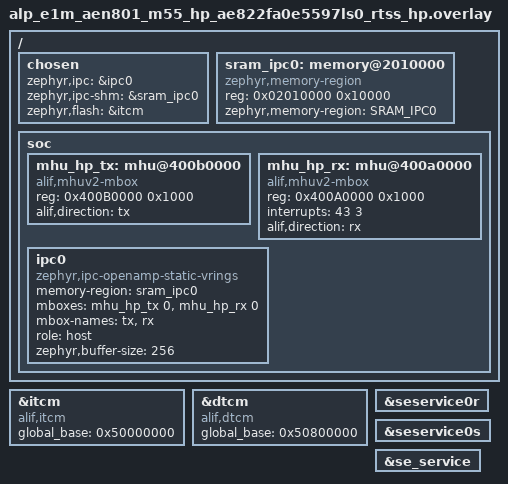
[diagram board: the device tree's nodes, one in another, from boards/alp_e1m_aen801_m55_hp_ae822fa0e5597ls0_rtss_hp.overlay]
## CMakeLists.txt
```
# SPDX-License-Identifier: Apache-2.0
#
# aen-alp-rpc -- the proven aen-rpc-pingpong transport driven through the
# portable <alp/rpc.h> surface.  Build for BOTH boards; each board's
# fully-qualified boards/<board>.overlay auto-applies (the MHU frames + shared
# SRAM0 carve-out + ipc0 host/remote + SE-service nodes).  The HP build is the
# host (boots HE, sends "ping"); the HE build is the remote (echoes "pong").
#
# NOTE: open-amp + libmetal are alp-sdk west projects (the manifest allowlists
# the Zephyr-pinned modules), so a `west update` fetches them and they are
# auto-discovered -- no manual -DEXTRA_ZEPHYR_MODULES for them:
#   west build -p always -b alp_e1m_aen801_m55_hp/ae822fa0e5597ls0/rtss_hp \
#       examples/aen/aen-alp-rpc -d build-hp -- \
#       "-DEXTRA_ZEPHYR_MODULES=/path/alp-sdk;/path/hal/alif"
cmake_minimum_required(VERSION 3.20)
find_package(Zephyr REQUIRED HINTS $ENV{ZEPHYR_BASE})
project(aen_alp_rpc LANGUAGES C)
target_sources(app PRIVATE src/main.c)
```

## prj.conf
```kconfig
# SPDX-License-Identifier: Apache-2.0
#
# aen-alp-rpc -- the bench-proven aen-rpc-pingpong transport (PR#205, 16/16
# PASS) driven through the portable <alp/rpc.h> surface instead of the raw
# ipc_service calls.  The Kconfig is identical to pingpong's: the alp_rpc
# Zephyr backend binds the very same ipc0 instance the pingpong example does
# (it resolves DT_CHOSEN(zephyr_ipc) and runs ipc_service_open_instance +
# ipc_service_register_endpoint behind alp_rpc_open()).
#
# Bench RAM-run: console is the Alp UART console on the E1M edge UART0 (see the
# console block below).

# CONFIG_ALP_SDK turns on the alp-sdk module sources (the dispatcher in
# src/rpc_dispatch.c + the Zephyr backend in src/backends/rpc/zephyr_drv.c) and
# the Tier-2 driver Kconfigs (CONFIG_MBOX_ALIF_MHUV2 / CONFIG_ARM_MHUV2 /
# CONFIG_HAS_ALIF_SE_SERVICES).
CONFIG_ALP_SDK=y

# --- IPC / OpenAMP stack ---------------------------------------------------
# MBOX is the doorbell class; CONFIG_MBOX_ALIF_MHUV2 builds the Alif MHUv2 MBOX
# driver (zephyr/drivers/mbox/mbox_alif_mhuv2.c) for the ipc0 'mboxes'.
CONFIG_MBOX=y
CONFIG_MBOX_ALIF_MHUV2=y

# ipc_service + the OpenAMP RPMsg static-vrings backend.  alp_rpc's backend
# requires all three (zephyr_drv.c #errors otherwise) and the Kconfig
# (ALP_SDK_RPC: depends on IPC_SERVICE_BACKEND_RPMSG && OPENAMP) gates on them.
CONFIG_IPC_SERVICE=y
CONFIG_IPC_SERVICE_BACKEND_RPMSG=y
CONFIG_OPENAMP=y

# The framed-RPC body in src/backends/rpc/zephyr_drv.c.  default-y once
# IPC_SERVICE_BACKEND_RPMSG is set, but pin it so the build is self-describing.
CONFIG_ALP_SDK_RPC=y

# OpenAMP/libmetal need a heap for the rpmsg virtio allocations + the RX work
# queue.  Size generously for the RAM-run.
CONFIG_HEAP_MEM_POOL_SIZE=16384
CONFIG_MAIN_STACK_SIZE=4096
CONFIG_SYSTEM_WORKQUEUE_STACK_SIZE=2048

# --- SE service (HP boots HE via the portable alp_mproc_boot_core) ---------
# CONFIG_ARM_MHUV2 builds the in-tree "arm,mhuv2" IPM driver
# (zephyr/drivers/ipm/ipm_arm_mhuv2.c) for the seservice0 transport;
# CONFIG_HAS_ALIF_SE_SERVICES compiles the hal_alif SE client the SDK's boot
# backend (CONFIG_ALP_SDK_MPROC_BOOT_ALIF_SE, default y) consumes.
CONFIG_ARM_MHUV2=y
CONFIG_HAS_ALIF_SE_SERVICES=y

# --- Console: Alp UART console -- E1M edge UART0 (Alif UART5, P3_4/P3_5, 115200
# 8N1, NS16550), the E1M-AEN801 carrier console. The board _defconfig already
# selects it; we set it explicitly here so the example is self-describing.
CONFIG_SERIAL=y
CONFIG_CONSOLE=y
CONFIG_UART_CONSOLE=y
CONFIG_UART_INTERRUPT_DRIVEN=y
# Serial-less bench? Comment the four lines above and uncomment these to read
# 'ram_console_buf' over SWD instead:
# CONFIG_RAM_CONSOLE=y
# CONFIG_RAM_CONSOLE_BUFFER_SIZE=2048
# CONFIG_UART_CONSOLE=n
CONFIG_PRINTK=y

# Keep LOG off to keep the image small + deterministic for this bench run.
# alp_rpc's zephyr_drv.c uses LOG_* but those are compiled out cleanly at
# LOG=n.
CONFIG_LOG=n

# DCACHE off: the SRAM0 shared region is addressed identically by both cores and
# carries the vrings; running it cached would need explicit flush/invalidate the
# static-vrings backend doesn't do for this carve-out.  Matches the bench's
# eth/NPU SRAM0 precedent and the proven pingpong config.
CONFIG_DCACHE=n
CONFIG_IPC_SERVICE_BACKEND_RPMSG_SHMEM_RESET=y
```

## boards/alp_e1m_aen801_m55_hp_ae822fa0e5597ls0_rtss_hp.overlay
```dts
/*
 * Copyright (c) 2026 Alp Lab AB
 * SPDX-License-Identifier: Apache-2.0
 *
 * aen-alp-rpc -- M55-HP (ipc0 HOST / vring master) overlay.
 *
 * Byte-for-byte the SAME transport the bench-proven aen-rpc-pingpong overlay
 * wires (PR#205, 16/16 PASS); the only thing that differs between the two
 * examples is the application code -- this one drives the round-trips through
 * the portable <alp/rpc.h> surface instead of the raw ipc_service calls.  The
 * alp_rpc Zephyr backend (src/backends/rpc/zephyr_drv.c) resolves
 * DT_CHOSEN(zephyr_ipc), so the chosen { zephyr,ipc = &ipc0 } node below is the
 * single hook that lets alp_rpc_open() find this exact ipc0 instance.
 *
 * Three pieces (all transcribed verbatim from the proven pingpong overlay):
 *
 *   1. SE-service nodes + per-core itcm/dtcm global_base -- the HP app releases
 *      HE via se_service_boot_cpu() (hal_alif se_service.c puts its outbound
 *      buffer through local_to_global(), which reads
 *      DT_PROP(itcm/dtcm, global_base)).  HP global TCM aliases ITCM 0x50000000
 *      / DTCM 0x50800000, from the zephyr_alif fork ensemble_rtss_hp.dtsi.
 *
 *   2. The two MHUv2 frames this core drives, via the alif,mhuv2-mbox MBOX
 *      driver (zephyr/drivers/mbox/mbox_alif_mhuv2.c).  HP is the host:
 *        - tx (HP -> HE) : non-secure MHU-1 per-core alias @0x400B0000
 *        - rx (HE -> HP) : MHU1 HP-RX window @0x400A0000, HP IRQ 43
 *      Addresses + IRQ are clean-room-transcribed from the Alif DFP E8 part
 *      (AE822FA0E5597, rtss_hp/soc.h):
 *        MHU_M55HE_M55HP_1_RX_BASE = 0x400A0000, MHU_M55HE_M55HP_1_RX_IRQn = 43
 *      The HE -> HP direction is bench-proven by aen-dualcore-doorbell
 *      (commit b81a3738) and by aen-rpc-pingpong (PR#205, 16/16).
 *
 *   3. A shared-memory carve-out in global SRAM0 + the ipc0 node.  SRAM0 global
 *      base 0x02000000 / size 4MB (DFP soc_features.h: SOC_FEAT_BULK_SRAM0_BASE
 *      / _SIZE) is identically addressable from both M55 cores, so the RPMsg
 *      static vrings live here.  Both overlays MUST agree on this region's base
 *      + size + buffer-size.
 *
 * vendor-ext, BENCH-UNVERIFIED for this example's app code; the transport
 * (MHU + vrings + ipc_service handshake) is the bench-proven pingpong config.
 */

#include <zephyr/dt-bindings/ipc_service/static_vrings.h>

/ {
	chosen {
		/* alp_rpc's zephyr_drv.c resolves DT_CHOSEN(zephyr_ipc). */
		zephyr,ipc     = &ipc0;
		zephyr,ipc-shm = &sram_ipc0;
	};

	/*
	 * Shared RPMsg region: SRAM0 @0x02010000, 64 KiB.  Placed 64 KiB above
	 * the SRAM0 base so it never overlaps the 0x0200_00xx bench beacons the
	 * app stamps.  zephyr,memory-region makes it a real linker region; both
	 * cores map the SAME global address.
	 */
	sram_ipc0: memory@2010000 {
		compatible = "zephyr,memory-region", "mmio-sram";
		reg = <0x02010000 0x10000>;
		zephyr,memory-region = "SRAM_IPC0";
	};

	soc {
		/*
		 * HP -> HE sender frame. The non-secure MHU-1 base is a CPU-RELATIVE
		 * ALIAS (proven in aen-dualcore-ipc): from HP, 0x400B0000 = "my TX to
		 * HE" and the fabric routes it into HE's RX @0x400A0000 -- the SAME
		 * pair the HE->HP doorbell uses, no separate MHU0 needed.
		 */
		mhu_hp_tx: mhu@400b0000 {
			compatible = "alif,mhuv2-mbox";
			reg = <0x400B0000 0x1000>;
			alif,direction = "tx";
			#mbox-cells = <1>;
			status = "okay";
		};

		/* HE -> HP receiver frame (MHU1 RX window). */
		mhu_hp_rx: mhu@400a0000 {
			compatible = "alif,mhuv2-mbox";
			reg = <0x400A0000 0x1000>;
			interrupts = <43 3>;
			alif,direction = "rx";
			#mbox-cells = <1>;
			status = "okay";
		};

		ipc0: ipc0 {
			compatible = "zephyr,ipc-openamp-static-vrings";
			memory-region = <&sram_ipc0>;
			mboxes = <&mhu_hp_tx 0>, <&mhu_hp_rx 0>;
			mbox-names = "tx", "rx";
			role = "host";
			zephyr,buffer-size = <256>;
			status = "okay";
		};
	};
};

/*
 * RAM-run: retarget ROM to ITCM (path-reference form &itcm; the phandle-array
 * form makes FLASH_SIZE=0 and overflows the link).
 */
/ {
	chosen {
		zephyr,flash = &itcm;
		/delete-property/ zephyr,code-partition;
	};
};

&itcm {
	compatible = "alif,itcm";
	global_base = <0x50000000>;
};

&dtcm {
	compatible = "alif,dtcm";
	global_base = <0x50800000>;
};

&seservice0r {
	status = "okay";
};

&seservice0s {
	status = "okay";
};

&se_service {
	status = "okay";
};
```

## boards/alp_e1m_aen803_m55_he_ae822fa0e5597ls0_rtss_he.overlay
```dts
/*
 * Copyright (c) 2026 Alp Lab AB
 * SPDX-License-Identifier: Apache-2.0
 *
 * aen-alp-rpc -- M55-HE (ipc0 REMOTE / vring slave) overlay.
 *
 * The mirror of the HP host overlay, and byte-for-byte the SAME transport the
 * bench-proven aen-rpc-pingpong HE overlay wires (PR#205, 16/16 PASS).  HE is
 * the remote, so its tx/rx frames are the OPPOSITE windows of the same two MHU
 * instances:
 *   - tx (HE -> HP) : MHU1 HE-TX window @0x400B0000, HE IRQ 44
 *   - rx (HP -> HE) : MHU1 HE-RX window @0x400A0000, HE IRQ 43 (per-core alias)
 *
 * Addresses + IRQ are clean-room-transcribed from the Alif DFP E8 part
 * (AE822FA0E5597, rtss_he/soc.h):
 *   MHU_M55HE_M55HP_1_TX_BASE = 0x400B0000, MHU_M55HE_M55HP_1_TX_IRQn = 44
 * The HE -> HP TX window (0x400B0000) is bench-proven by aen-dualcore-doorbell
 * (commit b81a3738) and aen-rpc-pingpong (PR#205).
 *
 * The shared SRAM0 carve-out (sram_ipc0 @0x02010000, 64 KiB) and the ipc0
 * buffer-size MUST match the HP overlay byte-for-byte -- the static vrings are
 * laid out by address, so host and remote have to agree.
 *
 * SE-service nodes + itcm/dtcm global_base are enabled here too: the HE app
 * does not itself call boot_cpu in this example, but keeping the SE transport
 * + the HE global TCM aliases (ITCM 0x58000000 / DTCM 0x58800000, from the fork
 * ensemble_rtss_he.dtsi) bound matches the proven pingpong HE overlay and keeps
 * the two builds symmetric.
 *
 * vendor-ext, BENCH-UNVERIFIED for this example's app code; the transport is
 * the bench-proven pingpong config.
 */

#include <zephyr/dt-bindings/ipc_service/static_vrings.h>

/ {
	chosen {
		zephyr,ipc     = &ipc0;
		zephyr,ipc-shm = &sram_ipc0;
	};

	sram_ipc0: memory@2010000 {
		compatible = "zephyr,memory-region", "mmio-sram";
		reg = <0x02010000 0x10000>;
		zephyr,memory-region = "SRAM_IPC0";
	};

	soc {
		/* HE -> HP sender frame (MHU1 TX window) -- bench-proven. */
		mhu_he_tx: mhu@400b0000 {
			compatible = "alif,mhuv2-mbox";
			reg = <0x400B0000 0x1000>;
			alif,direction = "tx";
			#mbox-cells = <1>;
			status = "okay";
		};

		/*
		 * HP -> HE receiver frame. Per-core MHU-1 alias (proven in
		 * aen-dualcore-ipc): from HE, 0x400A0000 = "my RX from HP", which the
		 * fabric feeds from HP's TX @0x400B0000 -- the same pair both
		 * directions, no separate MHU0.
		 */
		mhu_he_rx: mhu@400a0000 {
			compatible = "alif,mhuv2-mbox";
			reg = <0x400A0000 0x1000>;
			interrupts = <43 3>;
			alif,direction = "rx";
			#mbox-cells = <1>;
			status = "okay";
		};

		ipc0: ipc0 {
			compatible = "zephyr,ipc-openamp-static-vrings";
			memory-region = <&sram_ipc0>;
			mboxes = <&mhu_he_tx 0>, <&mhu_he_rx 0>;
			mbox-names = "tx", "rx";
			role = "remote";
			zephyr,buffer-size = <256>;
			status = "okay";
		};
	};
};

/*
 * RAM-run: retarget ROM to ITCM.
 */
/ {
	chosen {
		zephyr,flash = &itcm;
		/delete-property/ zephyr,code-partition;
	};
};

&itcm {
	compatible = "alif,itcm";
	global_base = <0x58000000>;
};

&dtcm {
	compatible = "alif,dtcm";
	global_base = <0x58800000>;
};

&seservice0r {
	status = "okay";
};

&seservice0s {
	status = "okay";
};

&se_service {
	status = "okay";
};
```

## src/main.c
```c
/*
 * Copyright (c) 2026 Alp Lab AB
 * SPDX-License-Identifier: Apache-2.0
 *
 * aen-alp-rpc -- the same E8 dual-M55 ping/pong as aen-rpc-pingpong (PR#205,
 * 16/16 PASS), but driven through the PORTABLE <alp/rpc.h> surface instead of
 * the raw Zephyr ipc_service calls.  This is the teaching example for the
 * framed-RPC API: it shows that customer code calls a handful of vendor-clean
 * alp_rpc_* functions while the alp_rpc Zephyr backend does the exact same
 * ipc_service_open_instance() + ipc_service_register_endpoint() dance the raw
 * pingpong does -- over the very same alif,mhuv2-mbox MBOX driver + shared
 * SRAM0 vring carve-out wired in the board overlays.
 *
 * Topology (identical to pingpong):
 *   - HP is the host: it releases HE via the portable alp_mproc_boot_core()
 *     (<alp/mproc.h>; the registry routes it to the SoM's boot authority --
 *     the SE boot service on AEN), opens the channel, subscribes to "pong",
 *     then sends 16 "ping" frames and counts the pongs.
 *   - HE is the remote: it opens the same channel, subscribes to "ping", and
 *     echoes every ping straight back as a "pong".
 *
 * Why two method names where pingpong used one endpoint?  The raw example put
 * BOTH the wire routing and the direction in a single ipc endpoint named
 * "pingpong".  The framed surface keeps the ipc endpoint name as the channel
 * IDENTITY (both cores MUST open the same alp_rpc_config_t::name so their
 * endpoints bind to each other), and moves the per-message routing into the
 * in-frame ASCII method header.  So one channel "alp_pingpong" carries two
 * methods: HP -> HE "ping", HE -> HP "pong".  alp_rpc_subscribe() filters by
 * method, so each side's callback only fires for the direction it cares about.
 *
 * Liveness/result mirrored to global-SRAM0 beacons (read over SWD; HE's console
 * is in HE-local memory -- same scheme + addresses as pingpong):
 *   HP: self+hb+verdict 0x02000010..18 | opened 0x02000048 | pongs 0x0200004C
 *   HE: self+hb+verdict 0x02001010..18 | opened 0x02001048 | pings 0x0200104C
 * SELF_BEACON[2] (the verdict word) is stamped with V_PASS/V_SKIP/V_FAIL right
 * before every return -- main() exits once it has a verdict instead of idling
 * forever, which would otherwise freeze the heartbeat and make a completed
 * run indistinguishable from a crash over SWD; the verdict word is what keeps
 * those two cases apart once the heartbeat has stopped moving.
 *
 * BENCH-UNVERIFIED for this example's app code; the transport (MHU + vrings +
 * ipc_service handshake) is the bench-proven pingpong config.
 */

#include <stdint.h>
#include <string.h>

#include <zephyr/kernel.h>
#include <zephyr/sys/printk.h>

#include <alp/mproc.h>
#include <alp/rpc.h>

/* Peer-core release (portable <alp/mproc.h>; same address pingpong uses). */
#define HE_LOAD_ADDR    0x58000000U /* HE ITCM global alias = HE-APP loadAddress */
#define PINGPONG_ROUNDS 16U

/* Bounded waits (see the file header: every wait here is bounded, named, and
 * commented -- an unbounded wait on a peer that's absent is exactly the hang
 * this app used to have). */
#define OPEN_SETTLE_MS    1500U /* fixed settle window for the async NS bind after open() */
#define ROUND_INTERVAL_MS 100U  /* HP: pacing between pings */
#define RESULT_GRACE_HB   5U    /* HP: extra heartbeats after the last ping before verdict */
/* HE: how long to keep echoing after the settle window before reporting a
 * verdict -- generous over HP's own PINGPONG_ROUNDS*ROUND_INTERVAL_MS drive
 * window plus its grace period. */
#define SERVE_WINDOW_MS 3000U

/* Verdict codes mirrored into SELF_BEACON[2] right before every return. */
#define V_PASS 1U
#define V_SKIP 2U
#define V_FAIL 3U

/*
 * The shared channel identity.  BOTH cores pass this exact string as
 * alp_rpc_config_t::name -- it becomes the ipc_service endpoint name, so the
 * host and remote endpoints bind to each other.  The two method names below
 * are the in-frame routing carried on top of that one channel.
 */
#define RPC_CHANNEL "alp_pingpong"
#define METHOD_PING "ping"
#define METHOD_PONG "pong"

/* Core-role selection (HP vs HE build of this app), not a peripheral-presence gate. */
#if defined(CONFIG_SOC_AE822FA0E5597LS0_RTSS_HP)
#define ROLE        "HP"
#define SELF_BEACON ((volatile uint32_t *)0x02000010U)
#define B_OPENED    ((volatile uint32_t *)0x02000048U)
#define B_CNT       ((volatile uint32_t *)0x0200004CU)
#define SELF_MAGIC  0xA1B10090U
#define IS_HOST     1
#else
#define ROLE        "HE"
#define SELF_BEACON ((volatile uint32_t *)0x02001010U)
#define B_OPENED    ((volatile uint32_t *)0x02001048U)
#define B_CNT       ((volatile uint32_t *)0x0200104CU)
#define SELF_MAGIC  0xA1B100E0U
#define IS_HOST     0
#endif

/* On-wire payload: a single round-trip sequence number. */
struct msg {
	uint32_t seq;
};

/* The open channel handle, shared between main() and the RX callbacks. */
static alp_rpc_channel_t *g_ch;
static volatile uint32_t  g_cnt; /* HP: pongs received | HE: pings received */

/* HE only: pongs SUCCESSFULLY sent back -- a separate counter from g_cnt,
 * since receiving a ping proves nothing about whether the echo that
 * followed actually went out. g_last_send_rc is the rc of the most recent
 * alp_rpc_send, for the FAIL message if every echo fails. */
static volatile uint32_t     g_echoed;
static volatile alp_status_t g_last_send_rc;

/*
 * Link-liveness demo (<alp/rpc.h>, issue #1643): alp_rpc_set_link_callback()
 * registers a callback that fires on every ALP_RPC_LINK_DOWN/_UP/_LOST
 * transition, so a real app can stop calling alp_rpc_send()/alp_rpc_call()
 * the moment it learns the peer is gone instead of finding out from a
 * timeout.  Just logged here -- this example's own PASS/FAIL verdict still
 * rests on the ping/pong counters above, not on this callback, since on
 * THIS board (an M55<->M55 pair, both sides Zephyr) the pinned ipc_service
 * RPMsg backend only ever calls `bound`, never `unbound`/`error` -- so in
 * this revision only ALP_RPC_LINK_UP is ever actually observed here.  See
 * src/backends/rpc/zephyr_drv.c's `@par Link liveness` file comment for why.
 */
static void on_link_state(alp_rpc_link_state_t state, void *user)
{
	ARG_UNUSED(user);
	printk("[%s] link state -> %d\n", ROLE, (int)state);
}

#if IS_HOST
/*
 * HP's "pong" handler: every echo HE sends back lands here.  alp_rpc has
 * already filtered by method, so we only need to count.  This runs on the
 * backend RX worker -- keep it short (the public-API contract in <alp/rpc.h>).
 */
static void on_pong(const void *payload, size_t len, void *user)
{
	ARG_UNUSED(user);
	if (len < sizeof(struct msg)) {
		return;
	}
	g_cnt++;
	*B_CNT = g_cnt;
}
#else
/*
 * HE's "ping" handler: echo the ping straight back to HP as a "pong" on the
 * same channel.  alp_rpc_send() frames (method + payload) and hands it to the
 * OpenAMP TX queue -- the mirror of pingpong's ipc_service_send().  The send
 * status is recorded, not discarded: a ping arriving here says nothing about
 * whether the echo that follows reaches HP.
 */
static void on_ping(const void *payload, size_t len, void *user)
{
	ARG_UNUSED(user);
	if (len < sizeof(struct msg)) {
		return;
	}
	const struct msg *m    = payload;
	struct msg        pong = { .seq = m->seq };

	g_cnt++;
	*B_CNT = g_cnt;

	alp_status_t src = alp_rpc_send(g_ch, METHOD_PONG, &pong, sizeof(pong));

	g_last_send_rc = src;
	if (src == ALP_OK) {
		g_echoed++;
	}
}
#endif

int main(void)
{
	printk("\n=== aen-alp-rpc (%s) ===\n", ROLE);
	SELF_BEACON[0] = SELF_MAGIC;
	SELF_BEACON[1] = 0U;
	SELF_BEACON[2] = 0U; /* verdict: none yet */
	*B_OPENED      = 0U;
	*B_CNT         = 0U;

#if IS_HOST
	/* HP releases the HE core before opening the channel, so HE is alive to
	 * bind its end of the endpoint (same as pingpong). A nonzero rc here means
	 * HE was never released, so nothing past this point (the channel, the
	 * subscribe) will ever bind -- that MUST be gated here, before any
	 * downstream code can claim a SKIP that implies local setup got further
	 * than it did. */
	alp_status_t brc = alp_mproc_boot_core(ALP_CORE_M55_HE, HE_LOAD_ADDR);

	printk("[HP] boot_core rc=%d\n", (int)brc);

	/* This build ships CONFIG_HAS_ALIF_SE_SERVICES=y and no native_sim
	 * overlay, so alp_mproc_boot_core() always resolves to the E8 SE
	 * backend for ALP_CORE_M55_HE (<alp/mproc.h>'s ALP_ERR_NOSUPPORT case
	 * -- "no boot authority for core in this build" -- is not reachable
	 * here). Any nonzero rc, NOSUPPORT included, is therefore a real
	 * local error: report it as FAIL, not a skippable environment state. */
	if (brc != ALP_OK) {
		SELF_BEACON[2] = V_FAIL;
		printk("RESULT FAIL: alp_mproc_boot_core rc=%d\n", (int)brc);
		return 0;
	}
#endif

	/*
	 * Open the RPC channel.  This is the whole point of the example: one call
	 * resolves DT_CHOSEN(zephyr_ipc) -> ipc0, opens the ipc_service instance,
	 * and registers the local endpoint -- exactly what the raw pingpong did by
	 * hand.  src/dst ept are left 0 so the backend derives them
	 * deterministically from the channel name (both cores hash the same
	 * name, so they agree).
	 */
	g_ch = alp_rpc_open(&(alp_rpc_config_t){
	    .name = RPC_CHANNEL,
	});
	if (g_ch == NULL) {
		/* alp_last_error() carries the reason (e.g. ALP_ERR_NOT_READY if the
		 * ipc0 chosen node is missing or the device isn't up yet). */
		SELF_BEACON[2] = V_FAIL;
		printk("[%s] alp_rpc_open failed: %d\n", ROLE, (int)alp_last_error());
		printk("RESULT FAIL: alp-rpc -- alp_rpc_open rc=%d\n", (int)alp_last_error());
		return 0;
	}
	*B_OPENED = 1U;
	printk("[%s] alp_rpc_open OK\n", ROLE);

	/* Register the link-liveness callback -- see on_link_state()'s doc
	 * comment above.  Best-effort: a NOSUPPORT rc here (e.g. a bare-metal
	 * stub build) doesn't change this example's verdict either way. */
	(void)alp_rpc_set_link_callback(g_ch, on_link_state, NULL);

	/*
	 * Subscribe to the direction this core consumes.  alp_rpc_subscribe()
	 * filters by method name, so each callback only fires for its own
	 * direction -- HP for "pong", HE for "ping".
	 */
#if IS_HOST
	alp_status_t src = alp_rpc_subscribe(g_ch, METHOD_PONG, on_pong, NULL);
#else
	alp_status_t src = alp_rpc_subscribe(g_ch, METHOD_PING, on_ping, NULL);
#endif
	printk("[%s] subscribe rc=%d\n", ROLE, (int)src);
	if (src != ALP_OK) {
		SELF_BEACON[2] = V_FAIL;
		printk("RESULT FAIL: alp-rpc -- alp_rpc_subscribe rc=%d\n", (int)src);
		alp_rpc_close(g_ch);
		return 0;
	}

	/*
	 * The OpenAMP name-service bind completes asynchronously after open().
	 * The framed surface doesn't expose a "bound" query, so -- exactly like
	 * pingpong waited on its on_bound flag -- give the handshake a fixed
	 * settle window before the host starts driving rounds.  The remote just
	 * services its RX worker the whole time.
	 */
	k_msleep(OPEN_SETTLE_MS);

#if IS_HOST
	/* HP drives the rounds: one "ping" per ROUND_INTERVAL_MS, tracking BOTH
	 * what was actually sent (send_ok / the last failing rc) and what came
	 * back (g_cnt) -- PASS must rest on the received evidence, but a local
	 * send failure has to surface as FAIL rather than being folded into
	 * "peer never responded". */
	uint32_t     send_ok      = 0U;
	alp_status_t last_send_rc = ALP_OK;

	for (uint32_t hb = 1U; hb <= PINGPONG_ROUNDS; hb++) {
		SELF_BEACON[1]    = hb;
		struct msg   ping = { .seq = hb };
		alp_status_t psrc = alp_rpc_send(g_ch, METHOD_PING, &ping, sizeof(ping));

		if (psrc == ALP_OK) {
			send_ok++;
		} else {
			last_send_rc = psrc;
		}
		k_msleep(ROUND_INTERVAL_MS);
	}
	/* Grace window: give the last few pongs time to arrive before evaluating. */
	for (uint32_t hb = PINGPONG_ROUNDS + 1U; hb <= PINGPONG_ROUNDS + RESULT_GRACE_HB; hb++) {
		SELF_BEACON[1] = hb;
		k_msleep(ROUND_INTERVAL_MS);
	}

	if (send_ok == 0U) {
		SELF_BEACON[2] = V_FAIL;
		printk("RESULT FAIL: alp-rpc -- alp_rpc_send rc=%d on all %u ping(s)\n",
		       (int)last_send_rc,
		       PINGPONG_ROUNDS);
	} else if (g_cnt >= PINGPONG_ROUNDS) {
		SELF_BEACON[2] = V_PASS;
		printk("RESULT PASS: alp-rpc -- received %u/%u pong(s) after sending %u ping(s)\n",
		       (unsigned)g_cnt,
		       PINGPONG_ROUNDS,
		       send_ok);
	} else {
		SELF_BEACON[2] = V_SKIP;
		printk("RESULT SKIP: alp-rpc -- sent %u ping(s), only %u/%u pong(s) came back "
		       "within the grace window; channel opened but peer stopped responding\n",
		       send_ok,
		       (unsigned)g_cnt,
		       PINGPONG_ROUNDS);
	}
#else
	/* HE: channel open + settled, so keep servicing echoes (on_ping does the
	 * real work) for a bounded window, then report what was actually proven
	 * locally. */
	for (uint32_t hb = 1U; hb <= SERVE_WINDOW_MS / ROUND_INTERVAL_MS; hb++) {
		SELF_BEACON[1] = hb;
		k_msleep(ROUND_INTERVAL_MS);
	}

	if (g_cnt == 0U) {
		SELF_BEACON[2] = V_SKIP;
		printk("RESULT SKIP: alp-rpc -- no ping arrived within %u ms; local alp_rpc_open "
		       "+ subscribe OK\n",
		       SERVE_WINDOW_MS);
	} else if (g_echoed < g_cnt) {
		/* PASS must rest on EVERY received ping being echoed -- a partial
		 * echo count (some alp_rpc_send calls failed) is a FAIL, not a
		 * PASS with a smaller numerator. */
		SELF_BEACON[2] = V_FAIL;
		printk("RESULT FAIL: alp-rpc -- received %u ping(s) but only %u echoed back; "
		       "last alp_rpc_send rc=%d\n",
		       (unsigned)g_cnt,
		       (unsigned)g_echoed,
		       (int)g_last_send_rc);
	} else {
		/* "queued": alp_rpc_send() == ALP_OK only means the frame was queued
		 * to the local vring -- HE never observes whether HP actually
		 * accepted it, so the verdict text must not claim delivery. */
		SELF_BEACON[2] = V_PASS;
		printk("RESULT PASS: alp-rpc -- queued %u/%u echo(es) for HP\n",
		       (unsigned)g_echoed,
		       (unsigned)g_cnt);
	}
#endif

	alp_rpc_close(g_ch);
	return 0;
}
```
